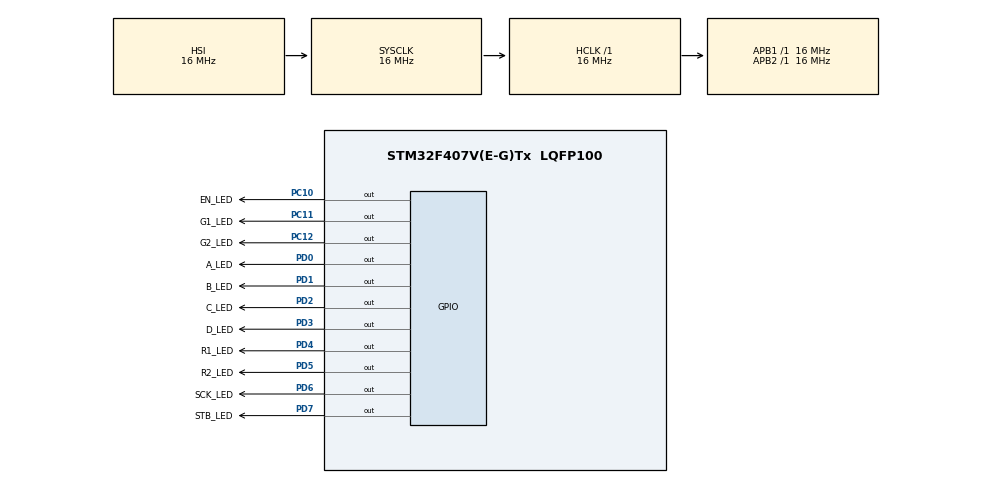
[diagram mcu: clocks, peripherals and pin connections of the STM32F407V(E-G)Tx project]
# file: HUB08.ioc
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Mcu.Family=STM32F4
Mcu.Name=STM32F407V(E-G)Tx
Mcu.Package=LQFP100
NVIC.PriorityGroup=NVIC_PRIORITYGROUP_4
PA13.Mode=Serial_Wire
PA13.Signal=SYS_JTMS-SWDIO
PA14.Mode=Serial_Wire
PA14.Signal=SYS_JTCK-SWCLK
PC10.GPIO_Label=EN_LED
PC10.GPIO_ModeDefaultOutputPP=GPIO_MODE_OUTPUT_PP
PC10.GPIO_PuPd=GPIO_NOPULL
PC10.GPIO_Speed=GPIO_SPEED_FREQ_VERY_HIGH
PC10.PinState=GPIO_PIN_SET
PC10.Signal=GPIO_Output
PC11.GPIO_Label=G1_LED
PC11.GPIO_Speed=GPIO_SPEED_FREQ_VERY_HIGH
PC11.PinState=GPIO_PIN_SET
PC11.Signal=GPIO_Output
PC12.GPIO_Label=G2_LED
PC12.GPIO_ModeDefaultOutputPP=GPIO_MODE_OUTPUT_PP
PC12.GPIO_PuPd=GPIO_NOPULL
PC12.GPIO_Speed=GPIO_SPEED_FREQ_VERY_HIGH
PC12.PinState=GPIO_PIN_SET
PC12.Signal=GPIO_Output
PD0.GPIO_Label=A_LED
PD0.GPIO_ModeDefaultOutputPP=GPIO_MODE_OUTPUT_PP
PD0.GPIO_PuPd=GPIO_NOPULL
PD0.GPIO_Speed=GPIO_SPEED_FREQ_VERY_HIGH
PD0.PinState=GPIO_PIN_SET
PD0.Signal=GPIO_Output
PD1.GPIO_Label=B_LED
PD1.GPIO_ModeDefaultOutputPP=GPIO_MODE_OUTPUT_PP
PD1.GPIO_PuPd=GPIO_NOPULL
PD1.GPIO_Speed=GPIO_SPEED_FREQ_VERY_HIGH
PD1.PinState=GPIO_PIN_SET
PD1.Signal=GPIO_Output
PD2.GPIO_Label=C_LED
PD2.GPIO_ModeDefaultOutputPP=GPIO_MODE_OUTPUT_PP
PD2.GPIO_PuPd=GPIO_NOPULL
PD2.GPIO_Speed=GPIO_SPEED_FREQ_VERY_HIGH
PD2.PinState=GPIO_PIN_SET
PD2.Signal=GPIO_Output
PD3.GPIO_Label=D_LED
PD3.GPIO_ModeDefaultOutputPP=GPIO_MODE_OUTPUT_PP
PD3.GPIO_PuPd=GPIO_NOPULL
PD3.GPIO_Speed=GPIO_SPEED_FREQ_VERY_HIGH
PD3.PinState=GPIO_PIN_SET
PD3.Signal=GPIO_Output
PD4.GPIO_Label=R1_LED
PD4.GPIO_ModeDefaultOutputPP=GPIO_MODE_OUTPUT_PP
PD4.GPIO_PuPd=GPIO_NOPULL
PD4.GPIO_Speed=GPIO_SPEED_FREQ_VERY_HIGH
PD4.PinState=GPIO_PIN_SET
PD4.Signal=GPIO_Output
PD5.GPIO_Label=R2_LED
PD5.GPIO_ModeDefaultOutputPP=GPIO_MODE_OUTPUT_PP
PD5.GPIO_PuPd=GPIO_NOPULL
PD5.GPIO_Speed=GPIO_SPEED_FREQ_VERY_HIGH
PD5.PinState=GPIO_PIN_SET
PD5.Signal=GPIO_Output
PD6.GPIO_Label=SCK_LED
PD6.GPIO_ModeDefaultOutputPP=GPIO_MODE_OUTPUT_PP
PD6.GPIO_PuPd=GPIO_NOPULL
PD6.GPIO_Speed=GPIO_SPEED_FREQ_VERY_HIGH
PD6.PinState=GPIO_PIN_SET
PD6.Signal=GPIO_Output
PD7.GPIO_Label=STB_LED
PD7.GPIO_ModeDefaultOutputPP=GPIO_MODE_OUTPUT_PP
PD7.GPIO_PuPd=GPIO_NOPULL
PD7.GPIO_Speed=GPIO_SPEED_FREQ_VERY_HIGH
PD7.PinState=GPIO_PIN_SET
PD7.Signal=GPIO_Output
PH0-OSC_IN.Mode=HSE-External-Oscillator
PH0-OSC_IN.Signal=RCC_OSC_IN
PH1-OSC_OUT.Mode=HSE-External-Oscillator
PH1-OSC_OUT.Signal=RCC_OSC_OUT
ProjectManager.HeapSize=0x200
ProjectManager.StackSize=0x400
ProjectManager.TargetToolchain=MDK-ARM V5.32
RCC.AHBFreq_Value=16000000
RCC.APB1Freq_Value=16000000
RCC.APB2Freq_Value=16000000
RCC.CortexFreq_Value=16000000
RCC.HSE_VALUE=25000000
RCC.HSI_VALUE=16000000
RCC.LSE_VALUE=32768
RCC.SYSCLKFreq_VALUE=16000000
RCC.VCOOutputFreq_Value=192000000
board=custom

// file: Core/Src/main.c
/* USER CODE BEGIN Header */
/**
  ******************************************************************************
  * @file           : main.c
  * @brief          : Main program body
  ******************************************************************************
  * @attention
  *
  * Copyright (c) 2024 STMicroelectronics.
  * All rights reserved.
  *
  * This software is licensed under terms that can be found in the LICENSE file
  * in the root directory of this software component.
  * If no LICENSE file comes with this software, it is provided AS-IS.
  *
  ******************************************************************************
  */
/* USER CODE END Header */
#include "main.h"
#include "gpio.h"

/* USER CODE BEGIN Includes */
#include "hub08.h"
/* USER CODE END Includes */

void SystemClock_Config(void);

int main(void)
{

  /* MCU Configuration--------------------------------------------------------*/

  /* Reset of all peripherals, Initializes the Flash interface and the Systick. */
  HAL_Init();

  /* Configure the system clock */
  SystemClock_Config();

  /* Initialize all configured peripherals */
  MX_GPIO_Init();
  /* USER CODE BEGIN 2 */
	Hub08_Init();
  /* USER CODE END 2 */

  /* Infinite loop */
  /* USER CODE BEGIN WHILE */
  while (1)
  {
		Hub08_View();
    /* USER CODE END WHILE */

  }
}

void SystemClock_Config(void)
{
  RCC_OscInitTypeDef RCC_OscInitStruct = {0};
  RCC_ClkInitTypeDef RCC_ClkInitStruct = {0};

  /** Configure the main internal regulator output voltage
  */
  __HAL_RCC_PWR_CLK_ENABLE();
  __HAL_PWR_VOLTAGESCALING_CONFIG(PWR_REGULATOR_VOLTAGE_SCALE1);

  /** Initializes the RCC Oscillators according to the specified parameters
  * in the RCC_OscInitTypeDef structure.
  */
  RCC_OscInitStruct.OscillatorType = RCC_OSCILLATORTYPE_HSI;
  RCC_OscInitStruct.HSIState = RCC_HSI_ON;
  RCC_OscInitStruct.HSICalibrationValue = RCC_HSICALIBRATION_DEFAULT;
  RCC_OscInitStruct.PLL.PLLState = RCC_PLL_NONE;
  if (HAL_RCC_OscConfig(&RCC_OscInitStruct) != HAL_OK)
  {
    Error_Handler();
  }

  /** Initializes the CPU, AHB and APB buses clocks
  */
  RCC_ClkInitStruct.ClockType = RCC_CLOCKTYPE_HCLK|RCC_CLOCKTYPE_SYSCLK
                              |RCC_CLOCKTYPE_PCLK1|RCC_CLOCKTYPE_PCLK2;
  RCC_ClkInitStruct.SYSCLKSource = RCC_SYSCLKSOURCE_HSI;
  RCC_ClkInitStruct.AHBCLKDivider = RCC_SYSCLK_DIV1;
  RCC_ClkInitStruct.APB1CLKDivider = RCC_HCLK_DIV1;
  RCC_ClkInitStruct.APB2CLKDivider = RCC_HCLK_DIV1;

  if (HAL_RCC_ClockConfig(&RCC_ClkInitStruct, FLASH_LATENCY_0) != HAL_OK)
  {
    Error_Handler();
  }
}

void Error_Handler(void)
{
  __disable_irq();
  while (1)
  {
  }
}
